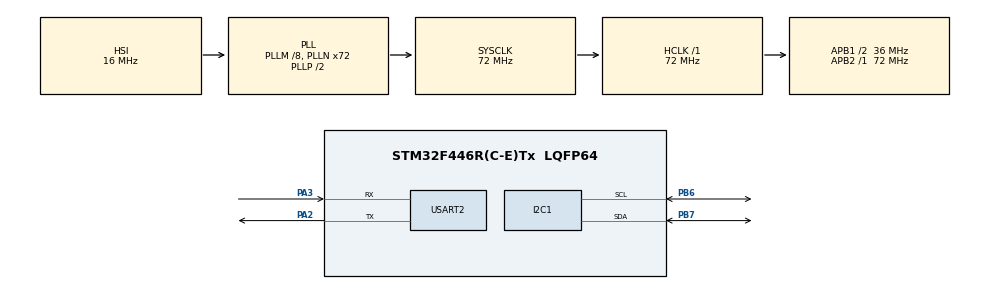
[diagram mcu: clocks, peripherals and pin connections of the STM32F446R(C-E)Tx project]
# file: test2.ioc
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Mcu.Family=STM32F4
Mcu.Name=STM32F446R(C-E)Tx
Mcu.Package=LQFP64
NVIC.PriorityGroup=NVIC_PRIORITYGROUP_4
PA13.Mode=Serial_Wire
PA13.Signal=SYS_JTMS-SWDIO
PA14.Mode=Serial_Wire
PA14.Signal=SYS_JTCK-SWCLK
PA2.Mode=Asynchronous
PA2.Signal=USART2_TX
PA3.Mode=Asynchronous
PA3.Signal=USART2_RX
PB6.Mode=I2C
PB6.Signal=I2C1_SCL
PB7.Mode=I2C
PB7.Signal=I2C1_SDA
ProjectManager.HeapSize=0x200
ProjectManager.StackSize=0x400
ProjectManager.TargetToolchain=STM32CubeIDE
RCC.AHBFreq_Value=72000000
RCC.APB1CLKDivider=RCC_HCLK_DIV2
RCC.APB1Freq_Value=36000000
RCC.APB1TimFreq_Value=72000000
RCC.APB2Freq_Value=72000000
RCC.APB2TimFreq_Value=72000000
RCC.CortexFreq_Value=72000000
RCC.HCLKFreq_Value=72000000
RCC.PLLM=8
RCC.PLLN=72
RCC.SYSCLKFreq_VALUE=72000000
RCC.SYSCLKSource=RCC_SYSCLKSOURCE_PLLCLK
RCC.USBFreq_Value=72000000
RCC.VCOOutputFreq_Value=144000000
USART2.VirtualMode=VM_ASYNC
board=custom

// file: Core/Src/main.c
#include "stm32f4xx_hal.h"
#include "mpu6050.h"
#include "EKF.h"
#include "INS.h"
#include <string.h>
#include <stdio.h>
#include <math.h>
#include "arm_math.h" // Must include for DSP types
#include "main.h"

/* USER CODE BEGIN Includes */
#define DEG_TO_RAD 0.01745329251994329576923690768489f
#define RAD_TO_DEG 57.295779513082320876798154814105f

/* USER CODE END Includes */
// MPU6050, EKF, and INS structures
MPU6050_Data_t MPU6050_Data;
EKF ekf;
INS_t ins;

// Timing
uint32_t last_tick = 0;
float dt = 0.0f;

I2C_HandleTypeDef hi2c1;

UART_HandleTypeDef huart2;

void SystemClock_Config(void);
static void MX_GPIO_Init(void);
static void MX_I2C1_Init(void);
static void MX_USART2_UART_Init(void);
// Retarget printf to UART
#ifdef __GNUC__
#define PUTCHAR_PROTOTYPE int __io_putchar(int ch)
#else
#define PUTCHAR_PROTOTYPE int fputc(int ch, FILE *f)
#endif
PUTCHAR_PROTOTYPE
{
  HAL_UART_Transmit(&huart2, (uint8_t *)&ch, 1, HAL_MAX_DELAY);
  return ch;
}

int main(void)
{

  /* MCU Configuration--------------------------------------------------------*/

  /* Reset of all peripherals, Initializes the Flash interface and the Systick. */
  HAL_Init();

  /* Configure the system clock */
  SystemClock_Config();

  /* Initialize all configured peripherals */
  MX_GPIO_Init();
  MX_I2C1_Init();
  MX_USART2_UART_Init();
  /* USER CODE BEGIN 2 */
  printf("Initializing MPU6050...\r\n");
      if (MPU6050_Init(&hi2c1) != HAL_OK) {
          printf("MPU6050 Initialization Failed\r\n");
          while (1);
      }
      printf("MPU6050 Initialized Successfully\r\n");

      // **FIX**: Initialize the EKF with single float values as required by the new function signature.
      // These values are now single floats representing the diagonal of the matrices.
      float P_initial = 1.0f;   // Initial covariance
      float Q_angle = 0.001f;   // Process noise for angles
      float R_accel = 0.1f;     // Measurement noise for accelerometer
      EKF_Init(&ekf, P_initial, Q_angle, R_accel);

      // Initialize the INS for position estimation
      INS_Init(&ins);

      last_tick = HAL_GetTick();

  /* USER CODE END 2 */

  /* Infinite loop */
  /* USER CODE BEGIN WHILE */
  while (1)
  {
	  uint32_t current_tick = HAL_GetTick();
	          dt = (float)(current_tick - last_tick) / 1000.0f;
	          last_tick = current_tick;
	          if (dt <= 0) dt = 0.01f;

	          // Read sensor data
	          MPU6050_Read_All(&hi2c1, &MPU6050_Data);

	          // Predict step with gyroscope data (convert deg/s to rad/s)
	          EKF_Predict(&ekf,
	                      MPU6050_Data.Gx * DEG_TO_RAD,
	                      MPU6050_Data.Gy * DEG_TO_RAD,
	                      MPU6050_Data.Gz * DEG_TO_RAD,
	                      dt);

	          // Update step with accelerometer data (convert g to m/s^2)
	          EKF_Update(&ekf,
	                     MPU6050_Data.Ax * G_MPS2,
	                     MPU6050_Data.Ay * G_MPS2,
	                     MPU6050_Data.Az * G_MPS2);

	          // Check if the sensor is approximately parallel to the ground
	          if (fabsf(ekf.phi_r) < (20.0f * DEG_TO_RAD) && fabsf(ekf.theta_r) < (20.0f * DEG_TO_RAD)) {
	              // If it is, update the INS to calculate position
	              INS_Update(&ins,
	                         ekf.phi_r, ekf.theta_r,
	                         MPU6050_Data.Ax, MPU6050_Data.Ay, MPU6050_Data.Az,
	                         dt);
	          } else {
	              // If it's tilted too much, reset velocity to prevent drift (Zero-velocity Update)
	              ins.velocity_x_mps = 0.0f;
	              ins.velocity_y_mps = 0.0f;
	          }

	          // Print results for debugging/plotting
	          printf("%.2f,%.2f\r\n", ekf.phi_r * (180.0f / PI), ekf.theta_r * (180.0f / PI));

	          HAL_Delay(10);
  }
  /* USER CODE END 3 */
}

void SystemClock_Config(void)
{
  RCC_OscInitTypeDef RCC_OscInitStruct = {0};
  RCC_ClkInitTypeDef RCC_ClkInitStruct = {0};

  /** Configure the main internal regulator output voltage
  */
  __HAL_RCC_PWR_CLK_ENABLE();
  __HAL_PWR_VOLTAGESCALING_CONFIG(PWR_REGULATOR_VOLTAGE_SCALE3);

  /** Initializes the RCC Oscillators according to the specified parameters
  * in the RCC_OscInitTypeDef structure.
  */
  RCC_OscInitStruct.OscillatorType = RCC_OSCILLATORTYPE_HSI;
  RCC_OscInitStruct.HSIState = RCC_HSI_ON;
  RCC_OscInitStruct.HSICalibrationValue = RCC_HSICALIBRATION_DEFAULT;
  RCC_OscInitStruct.PLL.PLLState = RCC_PLL_ON;
  RCC_OscInitStruct.PLL.PLLSource = RCC_PLLSOURCE_HSI;
  RCC_OscInitStruct.PLL.PLLM = 8;
  RCC_OscInitStruct.PLL.PLLN = 72;
  RCC_OscInitStruct.PLL.PLLP = RCC_PLLP_DIV2;
  RCC_OscInitStruct.PLL.PLLQ = 2;
  RCC_OscInitStruct.PLL.PLLR = 2;
  if (HAL_RCC_OscConfig(&RCC_OscInitStruct) != HAL_OK)
  {
    Error_Handler();
  }

  /** Initializes the CPU, AHB and APB buses clocks
  */
  RCC_ClkInitStruct.ClockType = RCC_CLOCKTYPE_HCLK|RCC_CLOCKTYPE_SYSCLK
                              |RCC_CLOCKTYPE_PCLK1|RCC_CLOCKTYPE_PCLK2;
  RCC_ClkInitStruct.SYSCLKSource = RCC_SYSCLKSOURCE_PLLCLK;
  RCC_ClkInitStruct.AHBCLKDivider = RCC_SYSCLK_DIV1;
  RCC_ClkInitStruct.APB1CLKDivider = RCC_HCLK_DIV2;
  RCC_ClkInitStruct.APB2CLKDivider = RCC_HCLK_DIV1;

  if (HAL_RCC_ClockConfig(&RCC_ClkInitStruct, FLASH_LATENCY_2) != HAL_OK)
  {
    Error_Handler();
  }
}

static void MX_I2C1_Init(void)
{

  hi2c1.Instance = I2C1;
  hi2c1.Init.ClockSpeed = 100000;
  hi2c1.Init.DutyCycle = I2C_DUTYCYCLE_2;
  hi2c1.Init.OwnAddress1 = 0;
  hi2c1.Init.AddressingMode = I2C_ADDRESSINGMODE_7BIT;
  hi2c1.Init.DualAddressMode = I2C_DUALADDRESS_DISABLE;
  hi2c1.Init.OwnAddress2 = 0;
  hi2c1.Init.GeneralCallMode = I2C_GENERALCALL_DISABLE;
  hi2c1.Init.NoStretchMode = I2C_NOSTRETCH_DISABLE;
  if (HAL_I2C_Init(&hi2c1) != HAL_OK)
  {
    Error_Handler();
  }

}

static void MX_USART2_UART_Init(void)
{

  huart2.Instance = USART2;
  huart2.Init.BaudRate = 115200;
  huart2.Init.WordLength = UART_WORDLENGTH_8B;
  huart2.Init.StopBits = UART_STOPBITS_1;
  huart2.Init.Parity = UART_PARITY_NONE;
  huart2.Init.Mode = UART_MODE_TX_RX;
  huart2.Init.HwFlowCtl = UART_HWCONTROL_NONE;
  huart2.Init.OverSampling = UART_OVERSAMPLING_16;
  if (HAL_UART_Init(&huart2) != HAL_OK)
  {
    Error_Handler();
  }

}

static void MX_GPIO_Init(void)
{

  /* GPIO Ports Clock Enable */
  __HAL_RCC_GPIOA_CLK_ENABLE();
  __HAL_RCC_GPIOB_CLK_ENABLE();

}

void Error_Handler(void)
{
  __disable_irq();
  while (1)
  {
  }
}
